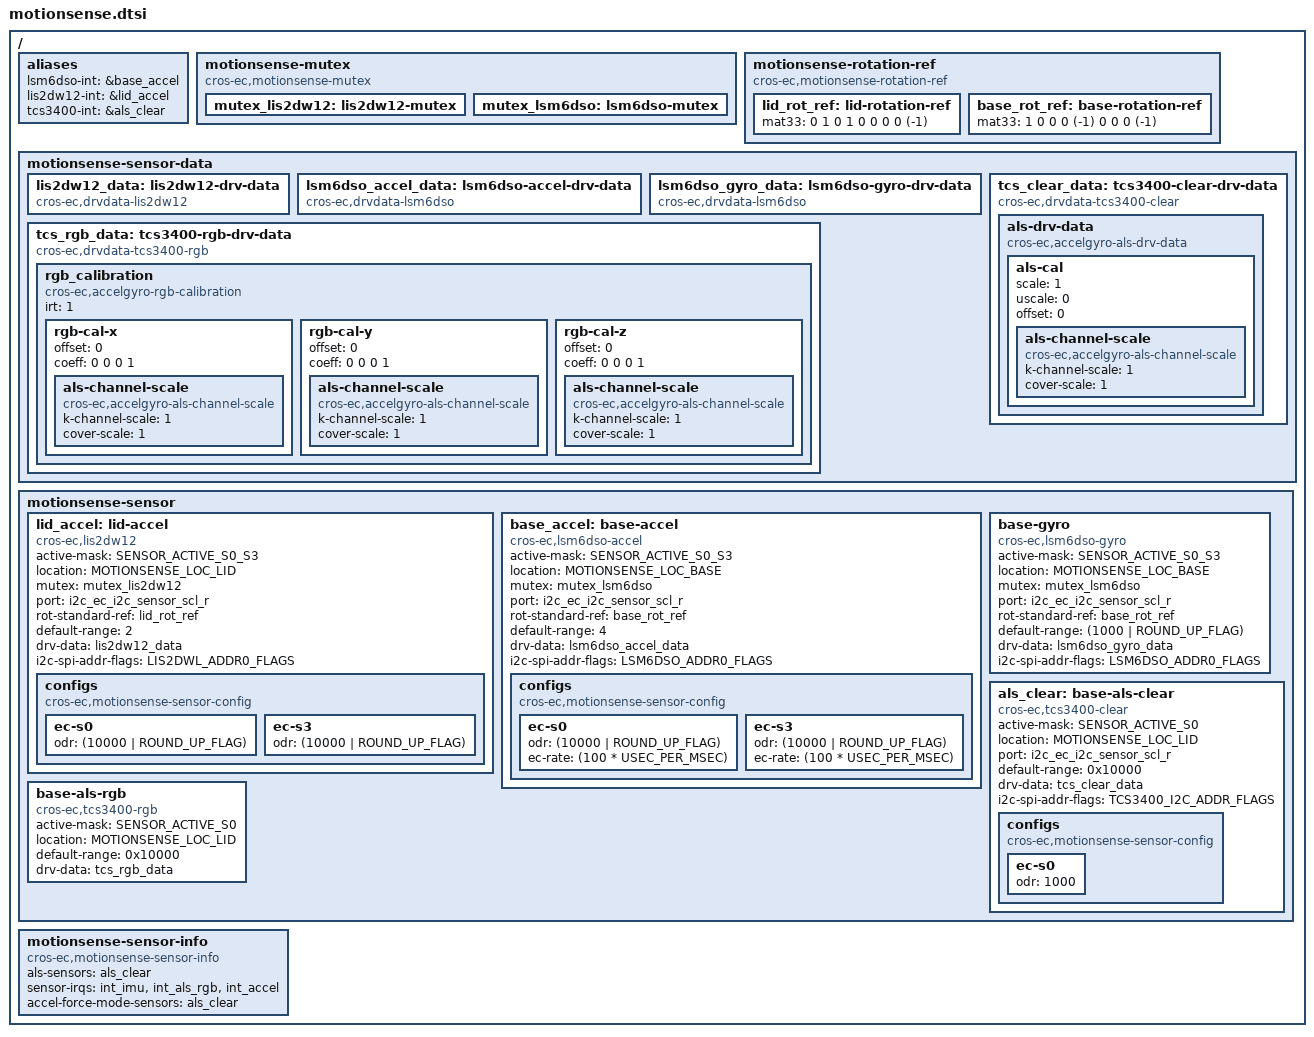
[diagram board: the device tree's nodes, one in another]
/*
 * Copyright 2022 The ChromiumOS Authors
 *
 * SPDX-License-Identifier: Apache-2.0
 */

#include <dt-bindings/motionsense/utils.h>


/ {
	aliases {
		/*
		 * motion sense's <>_INT_EVENT is handled
		 * by alias. Using the alias, each driver creates
		 * its own <>_INT_EVENT.
		 */
		lsm6dso-int = &base_accel;
		lis2dw12-int = &lid_accel;
		tcs3400-int = &als_clear;
	};

	/*
	 * Declare mutexes used by sensor drivers.
	 * A mutex node is used to create an instance of mutex_t.
	 * A mutex node is referenced by a sensor node if the
	 * corresponding sensor driver needs to use the
	 * instance of the mutex.
	 */
	motionsense-mutex {
		compatible = "cros-ec,motionsense-mutex";
		mutex_lis2dw12: lis2dw12-mutex {
		};

		mutex_lsm6dso: lsm6dso-mutex {
		};
	};

	/* Rotation matrix used by drivers. */
	motionsense-rotation-ref {
		compatible = "cros-ec,motionsense-rotation-ref";
		lid_rot_ref: lid-rotation-ref {
			mat33 = <0 1 0
				 1 0 0
				 0 0 (-1)>;
		};
		base_rot_ref: base-rotation-ref {
			mat33 = <1 0 0
				 0 (-1) 0
				 0 0 (-1)>;
		};
	};

	/*
	 * Driver specific data. A driver-specific data can be shared with
	 * different motion sensors while they are using the same driver.
	 *
	 * If a node's compatible starts with "cros-ec,accelgyro-", it is for
	 * a common structure defined in accelgyro.h.
	 * e.g) compatible = "cros-ec,accelgyro-als-drv-data" is for
	 * "struct als_drv_data_t" in accelgyro.h
	 */
	motionsense-sensor-data {
		lis2dw12_data: lis2dw12-drv-data {
			compatible = "cros-ec,drvdata-lis2dw12";
			status = "okay";
		};

		lsm6dso_accel_data: lsm6dso-accel-drv-data {
			compatible = "cros-ec,drvdata-lsm6dso";
			status = "okay";
		};

		lsm6dso_gyro_data: lsm6dso-gyro-drv-data {
			compatible = "cros-ec,drvdata-lsm6dso";
			status = "okay";
		};

		tcs_clear_data: tcs3400-clear-drv-data {
			compatible = "cros-ec,drvdata-tcs3400-clear";
			status = "okay";

			als-drv-data {
				compatible = "cros-ec,accelgyro-als-drv-data";
				als-cal {
					scale = <1>;
					uscale = <0>;
					offset = <0>;
					als-channel-scale {
					compatible =
					"cros-ec,accelgyro-als-channel-scale";
						k-channel-scale = <1>;
						cover-scale = <1>;
					};
				};
			};
		};

		tcs_rgb_data: tcs3400-rgb-drv-data {
			compatible = "cros-ec,drvdata-tcs3400-rgb";
			status = "okay";

			/* node for rgb_calibration_t defined in accelgyro.h */
			rgb_calibration {
				compatible =
					"cros-ec,accelgyro-rgb-calibration";

				irt = <1>;

				rgb-cal-x {
					offset = <0>;
					coeff = <0 0 0 1>;
					als-channel-scale {
					compatible =
					"cros-ec,accelgyro-als-channel-scale";
						k-channel-scale = <1>;
						cover-scale = <1>;
					};
				};
				rgb-cal-y {
					offset = <0>;
					coeff = <0 0 0 1>;
					als-channel-scale {
					compatible =
					"cros-ec,accelgyro-als-channel-scale";
						k-channel-scale = <1>;
						cover-scale = <1>;
					};
				};
				rgb-cal-z {
					offset = <0>;
					coeff = <0 0 0 1>;
					als-channel-scale {
					compatible =
					"cros-ec,accelgyro-als-channel-scale";
						k-channel-scale = <1>;
						cover-scale = <1>;
					};
				};
			};
		};
	};

	/*
	 * List of motion sensors that creates motion_sensors array.
	 * The nodelabel "lid_accel" and "base_accel" are used to indicate
	 * motion sensor IDs for lid angle calculation.
	 */
	motionsense-sensor {
		lid_accel: lid-accel {
			compatible = "cros-ec,lis2dw12";
			status = "okay";

			active-mask = "SENSOR_ACTIVE_S0_S3";
			location = "MOTIONSENSE_LOC_LID";
			mutex = <&mutex_lis2dw12>;
			port = <&i2c_ec_i2c_sensor_scl_r>;
			rot-standard-ref = <&lid_rot_ref>;
			default-range = <2>;
			drv-data = <&lis2dw12_data>;
			i2c-spi-addr-flags = "LIS2DWL_ADDR0_FLAGS";
			configs {
				compatible =
					"cros-ec,motionsense-sensor-config";
				ec-s0 {
					odr = <(10000 | ROUND_UP_FLAG)>;
				};
				ec-s3 {
					odr = <(10000 | ROUND_UP_FLAG)>;
				};
			};
		};

		base_accel: base-accel {
			compatible = "cros-ec,lsm6dso-accel";
			status = "okay";

			active-mask = "SENSOR_ACTIVE_S0_S3";
			location = "MOTIONSENSE_LOC_BASE";
			mutex = <&mutex_lsm6dso>;
			port = <&i2c_ec_i2c_sensor_scl_r>;
			rot-standard-ref = <&base_rot_ref>;
			default-range = <4>;
			drv-data = <&lsm6dso_accel_data>;
			i2c-spi-addr-flags = "LSM6DSO_ADDR0_FLAGS";
			configs {
				compatible =
					"cros-ec,motionsense-sensor-config";
				ec-s0 {
					odr = <(10000 | ROUND_UP_FLAG)>;
					ec-rate = <(100 * USEC_PER_MSEC)>;
				};
				ec-s3 {
					odr = <(10000 | ROUND_UP_FLAG)>;
					ec-rate = <(100 * USEC_PER_MSEC)>;
				};
			};
		};

		base-gyro {
			compatible = "cros-ec,lsm6dso-gyro";
			status = "okay";

			active-mask = "SENSOR_ACTIVE_S0_S3";
			location = "MOTIONSENSE_LOC_BASE";
			mutex = <&mutex_lsm6dso>;
			port = <&i2c_ec_i2c_sensor_scl_r>;
			rot-standard-ref = <&base_rot_ref>;
			default-range = <(1000 | ROUND_UP_FLAG)>; /* dps */
			drv-data = <&lsm6dso_gyro_data>;
			i2c-spi-addr-flags = "LSM6DSO_ADDR0_FLAGS";
		};

		als_clear: base-als-clear {
			compatible = "cros-ec,tcs3400-clear";
			status = "okay";

			active-mask = "SENSOR_ACTIVE_S0";
			location = "MOTIONSENSE_LOC_LID";
			port = <&i2c_ec_i2c_sensor_scl_r>;
			default-range = <0x10000>;
			drv-data = <&tcs_clear_data>;
			i2c-spi-addr-flags = "TCS3400_I2C_ADDR_FLAGS";
			configs {
				compatible =
					"cros-ec,motionsense-sensor-config";
				ec-s0 {
					/* Run ALS sensor in S0 */
					odr = <1000>;
				};
			};
		};

		base-als-rgb {
			compatible = "cros-ec,tcs3400-rgb";
			status = "okay";

			active-mask = "SENSOR_ACTIVE_S0";
			location = "MOTIONSENSE_LOC_LID";
			default-range = <0x10000>; /* scale = 1x, uscale = 0 */
			drv-data = <&tcs_rgb_data>;
		};
	};

	motionsense-sensor-info {
		compatible = "cros-ec,motionsense-sensor-info";

		/* list of entries for motion_als_sensors */
		als-sensors = <&als_clear>;
		/*
		 * list of GPIO interrupts that have to
		 * be enabled at initial stage
		 */
		sensor-irqs = <&int_imu &int_als_rgb &int_accel>;
		/* list of sensors in force mode */
		accel-force-mode-sensors = <&als_clear>;
	};
};
